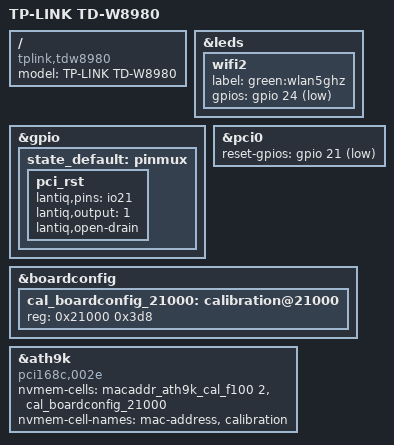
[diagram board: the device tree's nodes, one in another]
#include "vr9_tplink_tdw89x0.dtsi"

/ {
	compatible = "tplink,tdw8980", "tplink,tdw89x0", "lantiq,xway", "lantiq,vr9";
	model = "TP-LINK TD-W8980";
};

&leds {
	wifi2 {
		label = "green:wlan5ghz";
		gpios = <&gpio 24 GPIO_ACTIVE_LOW>;
	};
};

&gpio {
	state_default: pinmux {
		pci_rst {
			lantiq,pins = "io21";
			lantiq,output = <1>;
			lantiq,open-drain;
		};
	};
};

&pci0 {
	status = "okay";

	reset-gpios = <&gpio 21 GPIO_ACTIVE_LOW>;
};

&boardconfig {
	cal_boardconfig_21000: calibration@21000 {
		reg = <0x21000 0x3d8>;
	};
};

&ath9k {
	compatible = "pci168c,002e";
	nvmem-cells = <&macaddr_ath9k_cal_f100 2>, <&cal_boardconfig_21000>;
	nvmem-cell-names = "mac-address", "calibration";
};
